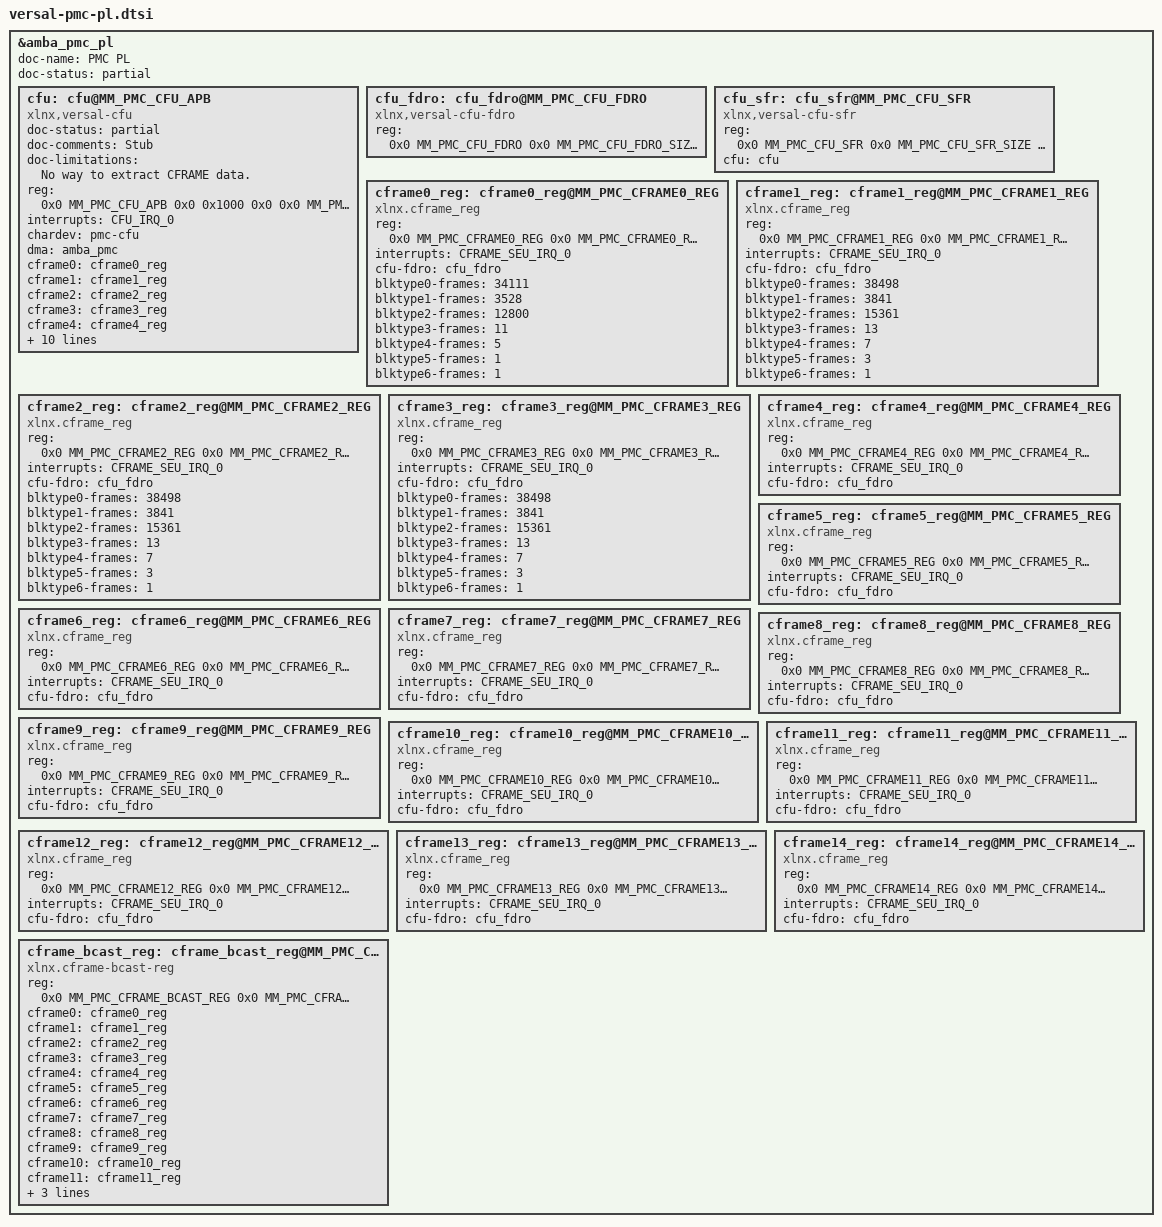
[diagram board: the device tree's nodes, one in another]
/*
 * Versal PMC PL Interfaces
 *
 * Copyright (c) 2016, Xilinx Inc
 * All rights reserved.
 *
 * Redistribution and use in source and binary forms, with or without
 * modification, are permitted provided that the following conditions are met:
 *     * Redistributions of source code must retain the above copyright
 *       notice, this list of conditions and the following disclaimer.
 *     * Redistributions in binary form must reproduce the above copyright
 *       notice, this list of conditions and the following disclaimer in the
 *       documentation and/or other materials provided with the distribution.
 *     * Neither the name of the <organization> nor the
 *       names of its contributors may be used to endorse or promote products
 *       derived from this software without specific prior written permission.
 *
 * THIS SOFTWARE IS PROVIDED BY THE COPYRIGHT HOLDERS AND CONTRIBUTORS "AS IS" AND
 * ANY EXPRESS OR IMPLIED WARRANTIES, INCLUDING, BUT NOT LIMITED TO, THE IMPLIED
 * WARRANTIES OF MERCHANTABILITY AND FITNESS FOR A PARTICULAR PURPOSE ARE
 * DISCLAIMED. IN NO EVENT SHALL <COPYRIGHT HOLDER> BE LIABLE FOR ANY
 * DIRECT, INDIRECT, INCIDENTAL, SPECIAL, EXEMPLARY, OR CONSEQUENTIAL DAMAGES
 * (INCLUDING, BUT NOT LIMITED TO, PROCUREMENT OF SUBSTITUTE GOODS OR SERVICES;
 * LOSS OF USE, DATA, OR PROFITS; OR BUSINESS INTERRUPTION) HOWEVER CAUSED AND
 * ON ANY THEORY OF LIABILITY, WHETHER IN CONTRACT, STRICT LIABILITY, OR TORT
 * (INCLUDING NEGLIGENCE OR OTHERWISE) ARISING IN ANY WAY OUT OF THE USE OF THIS
 * SOFTWARE, EVEN IF ADVISED OF THE POSSIBILITY OF SUCH DAMAGE.
 */

#include "versal.dtsh"

&amba_pmc_pl {
	doc-name = "PMC PL";
	doc-status = "partial";

	cfu: cfu@MM_PMC_CFU_APB {
		doc-status = "partial";
		doc-comments = "Stub";
		doc-limitations = "No way to extract CFRAME data.";

		compatible = "xlnx,versal-cfu";
		reg = <0x0 MM_PMC_CFU_APB 0x0 0x1000 0x0
		       0x0 MM_PMC_CFU_STREAM 0x0 MM_PMC_CFU_STREAM_SIZE 0x0
		       0x0 MM_PMC_CFU_STREAM_2 0x0 MM_PMC_CFU_STREAM_2_SIZE 0x0>;
		interrupts = <CFU_IRQ_0>;
		chardev = "pmc-cfu";
		dma = <&amba_pmc>;
		cframe0 = <&cframe0_reg>;
		cframe1 = <&cframe1_reg>;
		cframe2 = <&cframe2_reg>;
		cframe3 = <&cframe3_reg>;
		cframe4 = <&cframe4_reg>;
		cframe5 = <&cframe5_reg>;
		cframe6 = <&cframe6_reg>;
		cframe7 = <&cframe7_reg>;
		cframe8 = <&cframe8_reg>;
		cframe9 = <&cframe9_reg>;
		cframe10 = <&cframe10_reg>;
		cframe11 = <&cframe11_reg>;
		cframe12 = <&cframe12_reg>;
		cframe13 = <&cframe13_reg>;
		cframe14 = <&cframe14_reg>;
	};
	cfu_fdro: cfu_fdro@MM_PMC_CFU_FDRO {
		compatible = "xlnx,versal-cfu-fdro";
		reg = <0x0 MM_PMC_CFU_FDRO 0x0 MM_PMC_CFU_FDRO_SIZE 0x0>;
	};
	cfu_sfr: cfu_sfr@MM_PMC_CFU_SFR {
		compatible = "xlnx,versal-cfu-sfr";
		reg = <0x0 MM_PMC_CFU_SFR 0x0 MM_PMC_CFU_SFR_SIZE 0x0>;
		cfu = <&cfu>;
	};
	cframe0_reg: cframe0_reg@MM_PMC_CFRAME0_REG {
		compatible = "xlnx.cframe_reg";
		reg = <0x0 MM_PMC_CFRAME0_REG 0x0 MM_PMC_CFRAME0_REG_SIZE 0x0
		       0x0 MM_PMC_CFRAME0_FDRI 0x0 MM_PMC_CFRAME0_FDRI_SIZE 0x0>;
		interrupts = <CFRAME_SEU_IRQ_0>;
		cfu-fdro = <&cfu_fdro>;
		blktype0-frames = <34111>;
		blktype1-frames = <3528>;
		blktype2-frames = <12800>;
		blktype3-frames = <11>;
		blktype4-frames = <5>;
		blktype5-frames = <1>;
		blktype6-frames = <1>;
	};
	cframe1_reg: cframe1_reg@MM_PMC_CFRAME1_REG {
		compatible = "xlnx.cframe_reg";
		reg = <0x0 MM_PMC_CFRAME1_REG 0x0 MM_PMC_CFRAME1_REG_SIZE 0x0
		       0x0 MM_PMC_CFRAME1_FDRI 0x0 MM_PMC_CFRAME1_FDRI_SIZE 0x0>;
		interrupts = <CFRAME_SEU_IRQ_0>;
		cfu-fdro = <&cfu_fdro>;
		blktype0-frames = <38498>;
		blktype1-frames = <3841>;
		blktype2-frames = <15361>;
		blktype3-frames = <13>;
		blktype4-frames = <7>;
		blktype5-frames = <3>;
		blktype6-frames = <1>;
	};
	cframe2_reg: cframe2_reg@MM_PMC_CFRAME2_REG {
		compatible = "xlnx.cframe_reg";
		reg = <0x0 MM_PMC_CFRAME2_REG 0x0 MM_PMC_CFRAME2_REG_SIZE 0x0
		       0x0 MM_PMC_CFRAME2_FDRI 0x0 MM_PMC_CFRAME2_FDRI_SIZE 0x0>;
		interrupts = <CFRAME_SEU_IRQ_0>;
		cfu-fdro = <&cfu_fdro>;
		blktype0-frames = <38498>;
		blktype1-frames = <3841>;
		blktype2-frames = <15361>;
		blktype3-frames = <13>;
		blktype4-frames = <7>;
		blktype5-frames = <3>;
		blktype6-frames = <1>;
	};
	cframe3_reg: cframe3_reg@MM_PMC_CFRAME3_REG {
		compatible = "xlnx.cframe_reg";
		reg = <0x0 MM_PMC_CFRAME3_REG 0x0 MM_PMC_CFRAME3_REG_SIZE 0x0
		       0x0 MM_PMC_CFRAME3_FDRI 0x0 MM_PMC_CFRAME3_FDRI_SIZE 0x0>;
		interrupts = <CFRAME_SEU_IRQ_0>;
		cfu-fdro = <&cfu_fdro>;
		blktype0-frames = <38498>;
		blktype1-frames = <3841>;
		blktype2-frames = <15361>;
		blktype3-frames = <13>;
		blktype4-frames = <7>;
		blktype5-frames = <3>;
		blktype6-frames = <1>;
	};
	cframe4_reg: cframe4_reg@MM_PMC_CFRAME4_REG {
		compatible = "xlnx.cframe_reg";
		reg = <0x0 MM_PMC_CFRAME4_REG 0x0 MM_PMC_CFRAME4_REG_SIZE 0x0
		       0x0 MM_PMC_CFRAME4_FDRI 0x0 MM_PMC_CFRAME4_FDRI_SIZE 0x0>;
		interrupts = <CFRAME_SEU_IRQ_0>;
		cfu-fdro = <&cfu_fdro>;
	};
	cframe5_reg: cframe5_reg@MM_PMC_CFRAME5_REG {
		compatible = "xlnx.cframe_reg";
		reg = <0x0 MM_PMC_CFRAME5_REG 0x0 MM_PMC_CFRAME5_REG_SIZE 0x0
		       0x0 MM_PMC_CFRAME5_FDRI 0x0 MM_PMC_CFRAME5_FDRI_SIZE 0x0>;
		interrupts = <CFRAME_SEU_IRQ_0>;
		cfu-fdro = <&cfu_fdro>;
	};
	cframe6_reg: cframe6_reg@MM_PMC_CFRAME6_REG {
		compatible = "xlnx.cframe_reg";
		reg = <0x0 MM_PMC_CFRAME6_REG 0x0 MM_PMC_CFRAME6_REG_SIZE 0x0
		       0x0 MM_PMC_CFRAME6_FDRI 0x0 MM_PMC_CFRAME6_FDRI_SIZE 0x0>;
		interrupts = <CFRAME_SEU_IRQ_0>;
		cfu-fdro = <&cfu_fdro>;
	};
	cframe7_reg: cframe7_reg@MM_PMC_CFRAME7_REG {
		compatible = "xlnx.cframe_reg";
		reg = <0x0 MM_PMC_CFRAME7_REG 0x0 MM_PMC_CFRAME7_REG_SIZE 0x0
		       0x0 MM_PMC_CFRAME7_FDRI 0x0 MM_PMC_CFRAME7_FDRI_SIZE 0x0>;
		interrupts = <CFRAME_SEU_IRQ_0>;
		cfu-fdro = <&cfu_fdro>;
	};
	cframe8_reg: cframe8_reg@MM_PMC_CFRAME8_REG {
		compatible = "xlnx.cframe_reg";
		reg = <0x0 MM_PMC_CFRAME8_REG 0x0 MM_PMC_CFRAME8_REG_SIZE 0x0
		       0x0 MM_PMC_CFRAME8_FDRI 0x0 MM_PMC_CFRAME8_FDRI_SIZE 0x0>;
		interrupts = <CFRAME_SEU_IRQ_0>;
		cfu-fdro = <&cfu_fdro>;
	};
	cframe9_reg: cframe9_reg@MM_PMC_CFRAME9_REG {
		compatible = "xlnx.cframe_reg";
		reg = <0x0 MM_PMC_CFRAME9_REG 0x0 MM_PMC_CFRAME9_REG_SIZE 0x0
		       0x0 MM_PMC_CFRAME9_FDRI 0x0 MM_PMC_CFRAME9_FDRI_SIZE 0x0>;
		interrupts = <CFRAME_SEU_IRQ_0>;
		cfu-fdro = <&cfu_fdro>;
	};
	cframe10_reg: cframe10_reg@MM_PMC_CFRAME10_REG {
		compatible = "xlnx.cframe_reg";
		reg = <0x0 MM_PMC_CFRAME10_REG 0x0 MM_PMC_CFRAME10_REG_SIZE 0x0
		       0x0 MM_PMC_CFRAME10_FDRI 0x0 MM_PMC_CFRAME10_FDRI_SIZE 0x0>;
		interrupts = <CFRAME_SEU_IRQ_0>;
		cfu-fdro = <&cfu_fdro>;
	};
	cframe11_reg: cframe11_reg@MM_PMC_CFRAME11_REG {
		compatible = "xlnx.cframe_reg";
		reg = <0x0 MM_PMC_CFRAME11_REG 0x0 MM_PMC_CFRAME11_REG_SIZE 0x0
		       0x0 MM_PMC_CFRAME11_FDRI 0x0 MM_PMC_CFRAME11_FDRI_SIZE 0x0>;
		interrupts = <CFRAME_SEU_IRQ_0>;
		cfu-fdro = <&cfu_fdro>;
	};
	cframe12_reg: cframe12_reg@MM_PMC_CFRAME12_REG {
		compatible = "xlnx.cframe_reg";
		reg = <0x0 MM_PMC_CFRAME12_REG 0x0 MM_PMC_CFRAME12_REG_SIZE 0x0
		       0x0 MM_PMC_CFRAME12_FDRI 0x0 MM_PMC_CFRAME12_FDRI_SIZE 0x0>;
		interrupts = <CFRAME_SEU_IRQ_0>;
		cfu-fdro = <&cfu_fdro>;
	};
	cframe13_reg: cframe13_reg@MM_PMC_CFRAME13_REG {
		compatible = "xlnx.cframe_reg";
		reg = <0x0 MM_PMC_CFRAME13_REG 0x0 MM_PMC_CFRAME13_REG_SIZE 0x0
		       0x0 MM_PMC_CFRAME13_FDRI 0x0 MM_PMC_CFRAME13_FDRI_SIZE 0x0>;
		interrupts = <CFRAME_SEU_IRQ_0>;
		cfu-fdro = <&cfu_fdro>;
	};
	cframe14_reg: cframe14_reg@MM_PMC_CFRAME14_REG {
		compatible = "xlnx.cframe_reg";
		reg = <0x0 MM_PMC_CFRAME14_REG 0x0 MM_PMC_CFRAME14_REG_SIZE 0x0
		       0x0 MM_PMC_CFRAME14_FDRI 0x0 MM_PMC_CFRAME14_FDRI_SIZE 0x0>;
		interrupts = <CFRAME_SEU_IRQ_0>;
		cfu-fdro = <&cfu_fdro>;
	};
	cframe_bcast_reg: cframe_bcast_reg@MM_PMC_CFRAME_BCAST_REG {
		compatible = "xlnx.cframe-bcast-reg";
		reg = <0x0 MM_PMC_CFRAME_BCAST_REG 0x0 MM_PMC_CFRAME_BCAST_REG_SIZE 0x0
		       0x0 MM_PMC_CFRAME_BCAST_FDRI 0x0 MM_PMC_CFRAME_BCAST_FDRI_SIZE 0x0>;
		cframe0 = <&cframe0_reg>;
		cframe1 = <&cframe1_reg>;
		cframe2 = <&cframe2_reg>;
		cframe3 = <&cframe3_reg>;
		cframe4 = <&cframe4_reg>;
		cframe5 = <&cframe5_reg>;
		cframe6 = <&cframe6_reg>;
		cframe7 = <&cframe7_reg>;
		cframe8 = <&cframe8_reg>;
		cframe9 = <&cframe9_reg>;
		cframe10 = <&cframe10_reg>;
		cframe11 = <&cframe11_reg>;
		cframe12 = <&cframe12_reg>;
		cframe13 = <&cframe13_reg>;
		cframe14 = <&cframe14_reg>;
	};
};
